# CH572SFR register map
Vendor: WCH Ltd.; Series: CH572; File version: 1.1
CPU: RISC-V r0p0, little endian, no MPU, no FPU, 2 interrupt priority bits
Registers are 32-bit, read-write, reset 0x0 unless marked. A register's access mark holds for its fields unless they carry their own. Offsets are from the block's base; [hi:lo] are bit positions.

## SYS — System Control Register
Base 0x40001000
0x00 R32_IWDG_KR wo reset not defined — WO, Watchdog key register, SAM
  [15:0] IWDG_KR — RO,KEY [15:0]: Key value
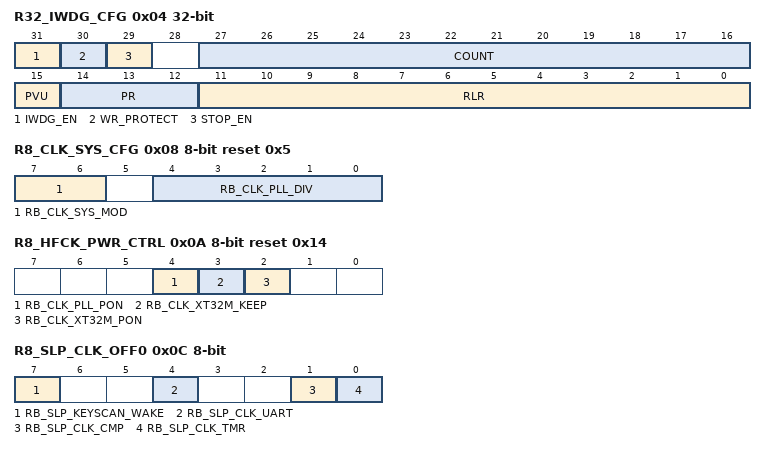
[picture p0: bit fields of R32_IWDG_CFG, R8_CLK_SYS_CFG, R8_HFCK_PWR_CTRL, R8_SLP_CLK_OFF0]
0x04 R32_IWDG_CFG reset not defined — RW, Watchdog configuration register, SAM
  [31] IWDG_EN ro — RW, Watch dog start switch: 1: ON; 0: Close
  [30] WR_PROTECT ro — RW, Write protection
  [29] STOP_EN ro — RW, Watchdog stop enabled (with write protection)
  [27:16] COUNT ro — RO, Watchdog countdown counter
  [15] PVU ro — RO, Configure register update flag bit (with write protection)
  [14:12] PR — RO, Pre division factor (with write protection)
  [11:0] RLR — RW, RL [11:0]: Watchdog counter reload
0x08 R8_CLK_SYS_CFG 8-bit reset 0x5 — RWA, system clock configuration, SAM
  [7:6] RB_CLK_SYS_MOD — RWA, system clock source mode: 00=divided from 32MHz
  [4:0] RB_CLK_PLL_DIV — RWA, output clock divider from PLL or CK32M
0x0A R8_HFCK_PWR_CTRL 8-bit reset 0x14 — RWA, High frequency clock module power control register, SAM
  [4] RB_CLK_PLL_PON — RWA, PLL power control bit
  [3] RB_CLK_XT32M_KEEP — RWA, Used to control the stopping of the clock system in pause mode
  [2] RB_CLK_XT32M_PON — RWA, External 32MHz oscillator HSE power control bit
0x0C R8_SLP_CLK_OFF0 8-bit — RWA, sleep clock off control byte 0, SAM
  [7] RB_SLP_KEYSCAN_WAKE — RWA, KEYSCAN wakeup enable
  [4] RB_SLP_CLK_UART — RWA, UART clock source
  [1] RB_SLP_CLK_CMP — RWA, CMP clock source
  [0] RB_SLP_CLK_TMR — RWA, Timer clock source
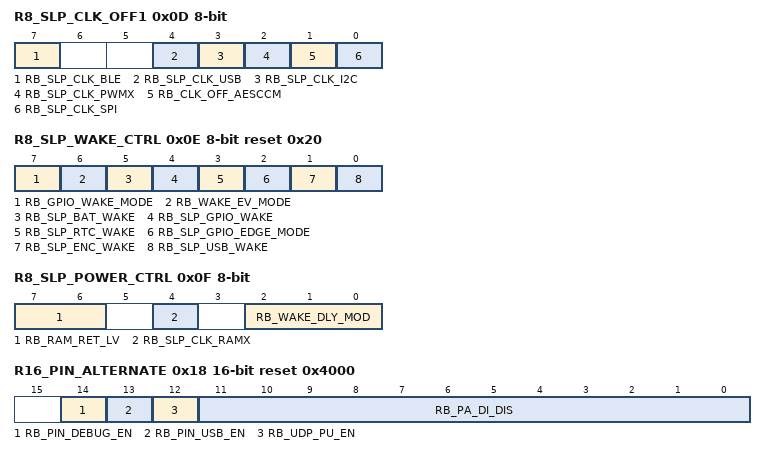
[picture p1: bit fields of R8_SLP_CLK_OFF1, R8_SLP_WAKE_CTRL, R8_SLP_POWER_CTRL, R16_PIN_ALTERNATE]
0x0D R8_SLP_CLK_OFF1 8-bit — RWA, sleep clock off control byte 1, SAM
  [7] RB_SLP_CLK_BLE — RWA, close BLE clock
  [4] RB_SLP_CLK_USB — RWA, close USB clock
  [3] RB_SLP_CLK_I2C — RWA, close I2C clock
  [2] RB_SLP_CLK_PWMX — RWA, close PWMx clock
  [1] RB_CLK_OFF_AESCCM — RWA, close AES_CCM clock
  [0] RB_SLP_CLK_SPI — RWA, close SPI clock
0x0E R8_SLP_WAKE_CTRL 8-bit reset 0x20 — RWA, wake control, SAM
  [7] RB_GPIO_WAKE_MODE — RWA, enable edge GPIO wake-up mode
  [6] RB_WAKE_EV_MODE — RWA, event wakeup mode
  [5] RB_SLP_BAT_WAKE — RWA, enable BAT waking
  [4] RB_SLP_GPIO_WAKE — RWA, enable GPIO waking
  [3] RB_SLP_RTC_WAKE — RWA, enable RTC waking
  [2] RB_SLP_GPIO_EDGE_MODE — RWA, GPIO wake-up mode selection
  [1] RB_SLP_ENC_WAKE — RWA, enable ENC waking
  [0] RB_SLP_USB_WAKE — RWA, enable USB waking
0x0F R8_SLP_POWER_CTRL 8-bit — RWA, peripherals power down control, SAM
  [7:6] RB_RAM_RET_LV — RWA, SRAM retention voltage selection
  [4] RB_SLP_CLK_RAMX — RWA, close main SRAM clock
  [2:0] RB_WAKE_DLY_MOD — RWA, wakeup delay time selection
0x18 R16_PIN_ALTERNATE 16-bit reset 0x4000 — RW, function pin alternate configuration
  [14] RB_PIN_DEBUG_EN — RW, Debugging interface control bit
  [13] RB_PIN_USB_EN — RW, Full speed USB pin enable
  [12] RB_UDP_PU_EN — RW, Enable internal pull-up resistor for UDP pin of full speed USB
  [11:0] RB_PA_DI_DIS — RW, PA0-PA11 channel pin digital input enable
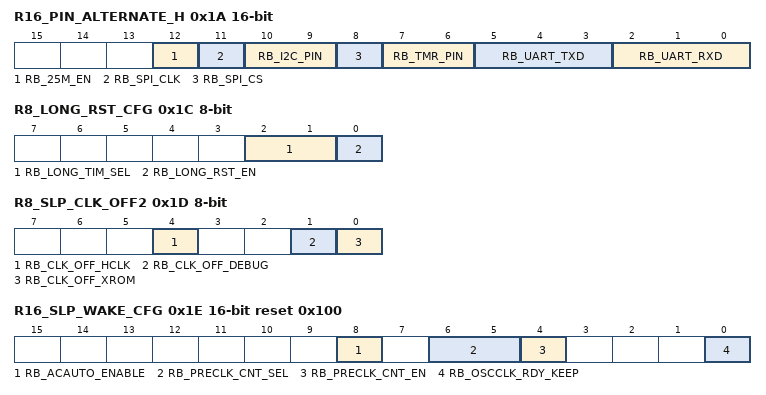
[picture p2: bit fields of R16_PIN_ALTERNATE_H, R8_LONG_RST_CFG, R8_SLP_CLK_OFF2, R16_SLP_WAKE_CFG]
0x1A R16_PIN_ALTERNATE_H 16-bit — RW, function pin high alternate configuration
  [12] RB_25M_EN — RW, Enable 25MHz clock output
  [11] RB_SPI_CLK — RW, SPI CLK function pin mapping selection bit
  [10:9] RB_I2C_PIN — RW, I2C function pin mapping selection bit
  [8] RB_SPI_CS — RW, SPI CS function pin mapping selection bit
  [7:6] RB_TMR_PIN — RW, Timer function pin mapping selection bit
  [5:3] RB_UART_TXD — RW, TXD alternate pin enable
  [2:0] RB_UART_RXD — RW, RXD alternate pin enable
0x1C R8_LONG_RST_CFG 8-bit — RWA, Long reset configuration register
  [2:1] RB_LONG_TIM_SEL — RWA, Long reset duration selection
  [0] RB_LONG_RST_EN — RWA, Long reset enable
0x1D R8_SLP_CLK_OFF2 8-bit — RWA, Sleep clock control register 2
  [4] RB_CLK_OFF_HCLK — RWA, Turn off the HCLK clock of the FLASH controller
  [1] RB_CLK_OFF_DEBUG — RWA, Close the two-wire debugging 32M clock
  [0] RB_CLK_OFF_XROM — RWA, Turn off the 64M or 600M clock of the FLASH controller
0x1E R16_SLP_WAKE_CFG 16-bit reset 0x100 — RWA, Sleep clock control register
  [8] RB_ACAUTO_ENABLE — RWA, The secure register channel automatically closes
  [6:5] RB_PRECLK_CNT_SEL — RWA, Sleep time configuration, sleep duration=number of cycles * Fsys
  [4] RB_PRECLK_CNT_EN — RWA, When waking up from sleep, it takes a certain amount of time to release HCLK
  [0] RB_OSCCLK_RDY_KEEP — RWA, During Halt sleep, the peripheral clock remains on
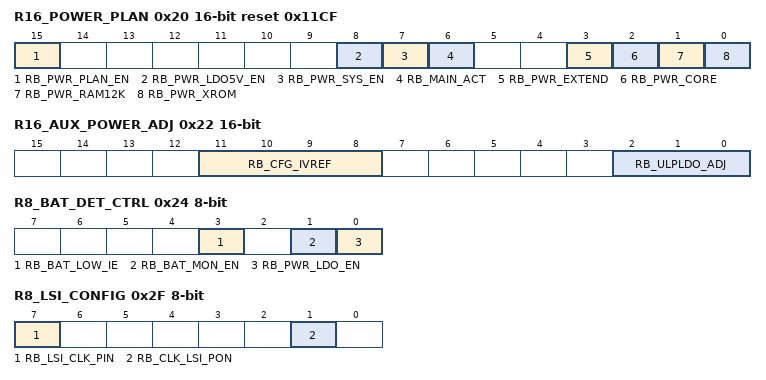
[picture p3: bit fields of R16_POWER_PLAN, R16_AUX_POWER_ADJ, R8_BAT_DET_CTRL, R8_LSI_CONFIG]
0x20 R16_POWER_PLAN 16-bit reset 0x11CF — RWA, power plan before sleep instruction, SAM
  [15] RB_PWR_PLAN_EN — RWA, Enable sleep power planning and control
  [8] RB_PWR_LDO5V_EN — RWA, Internal LDO5V control
  [7] RB_PWR_SYS_EN — RWA, power for system
  [6] RB_MAIN_ACT — RWA, Main power selection
  [3] RB_PWR_EXTEND — RWA, power retention for USB and BLE
  [2] RB_PWR_CORE — RWA, power retention for core and base peripherals
  [1] RB_PWR_RAM12K — RWA, SRAM power supply for RAM12K
  [0] RB_PWR_XROM — RWA, power for FlashROM
0x22 R16_AUX_POWER_ADJ 16-bit reset not defined — RWA, aux power adjust control, SAM
  [11:8] RB_CFG_IVREF — RO, retain. The original value must be kept unchanged when writing
  [2:0] RB_ULPLDO_ADJ — RWA, Output voltage regulation value of auxiliary power supply for ultra-low power consumption LDO
0x24 R8_BAT_DET_CTRL 8-bit — RWA, battery voltage detector control, SAM
  [3] RB_BAT_LOW_IE — RWA, Battery low voltage interrupt enable
  [1] RB_BAT_MON_EN — RWA, Enable low-power battery voltage monitoring function
  [0] RB_PWR_LDO_EN — RWA, -
0x25 R8_BAT_DET_CFG 8-bit reset 0x2 — RWA, battery voltage detector configuration, SAM
  [1:0] RB_BAT_LOW_VTH — RWA, select threshold voltage of battery voltage low
0x26 R8_BAT_STATUS 8-bit ro — RO, battery status
  [1] RB_BAT_STAT_LOW — RO, battery low voltage status, high action
0x2F R8_LSI_CONFIG 8-bit reset not defined — RWA, LSI configure register
  [7] RB_LSI_CLK_PIN — RO, LSI clock pin status (asynchronous signal)
  [1] RB_CLK_LSI_PON — RWA, Internal low-frequency RC oscillator LSI power control bit
